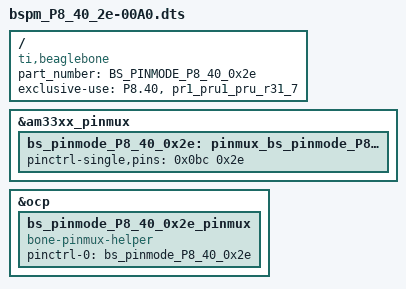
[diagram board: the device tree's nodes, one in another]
/*
 * This is a template-generated file from BoneScript
 */

/dts-v1/;
/plugin/;

/{
    compatible = "ti,beaglebone", "ti,beaglebone-black";
    part_number = "BS_PINMODE_P8_40_0x2e";

    exclusive-use =
        "P8.40",
        "pr1_pru1_pru_r31_7";

    fragment@0 {
        target = <&am33xx_pinmux>;
        __overlay__ {
            bs_pinmode_P8_40_0x2e: pinmux_bs_pinmode_P8_40_0x2e {
                pinctrl-single,pins = <0x0bc 0x2e>;
            };
        };
    };

    fragment@1 {
        target = <&ocp>;
        __overlay__ {
            bs_pinmode_P8_40_0x2e_pinmux {
                compatible = "bone-pinmux-helper";
                status = "okay";
                pinctrl-names = "default";
                pinctrl-0 = <&bs_pinmode_P8_40_0x2e>;
            };
        };
    };
};
